# S6E1A1 register map
File version: 1.2
CPU: 
Registers are 32-bit, read-write, reset 0x0 unless marked. A register's access mark holds for its fields unless they carry their own. Offsets are from the block's base; [hi:lo] are bit positions; {n}, {i} and the like mark numbered series.

## LVD — Low-voltage Detection
Base 0x40035000
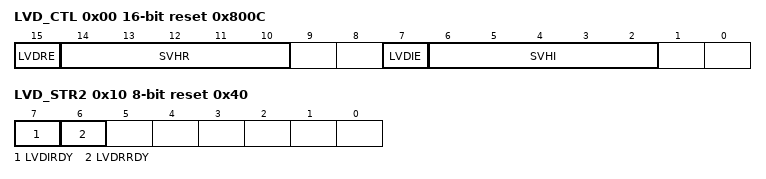
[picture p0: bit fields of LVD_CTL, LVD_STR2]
0x00 LVD_CTL 16-bit reset 0x800C — Low-voltage Detection Voltage Control Register
  [15] LVDRE — Low-voltage detection reset operation enable bit
  [14:10] SVHR — Low-voltage detection reset voltage setting bits
  [7] LVDIE — Low-voltage detection interrupt enable bit
  [6:2] SVHI — Low-voltage detection interrupt voltage setting bits
0x04 LVD_STR 8-bit ro — Low-voltage Detection Interrupt Factor Register
  [7] LVDIR — Low-voltage detection interrupt factor bit
0x08 LVD_CLR 8-bit reset 0x80 — Low-voltage Detection Interrupt Factor Clear Register
  [7] LVDCL — Low-voltage detection interrupt factor clear bit
0x0C LVD_RLR reset 0x1 — Low-voltage Detection Voltage Protection Register
  [31:0] LVDLCK — Low-voltage Detection Voltage Control Register protection bits
0x10 LVD_STR2 8-bit ro reset 0x40 — Low-voltage Detection Circuit Status Register
  [7] LVDIRDY — Low-voltage detection interrupt status flag
  [6] LVDRRDY — Low-voltage detection reset status flag

## DS — Low Power Consumption Mode Registers
Base 0x40035100
0x00 REG_CTL 8-bit reset 0x4 — Sub Oscillation Circuit Power Supply Control Register
  [2:1] ISUBSEL — Sub oscillation circuit current setting bits
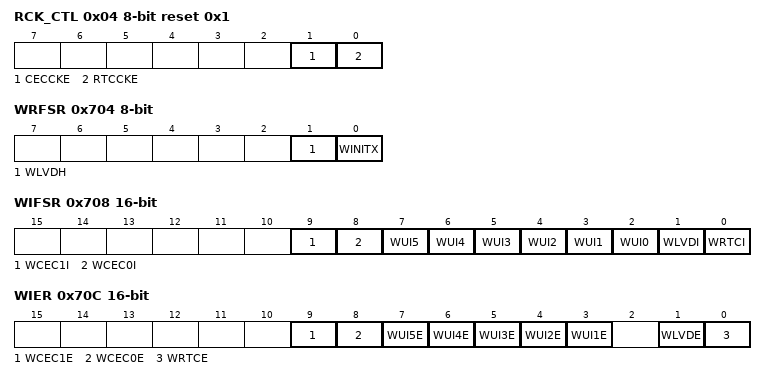
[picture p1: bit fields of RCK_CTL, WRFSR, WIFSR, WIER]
0x04 RCK_CTL 8-bit reset 0x1 — Sub Clock Control Register
  [1] CECCKE — CEC clock control bit
  [0] RTCCKE — RTC clock control bit
0x700 PMD_CTL 8-bit — RTC Mode Control Register
  [0] RTCE — RTC mode control bit
0x704 WRFSR 8-bit ro — Deep Standby Return Factor Register 1
  [1] WLVDH — Low-voltage detection reset return bit
  [0] WINITX — INITX pin input reset return bit
0x708 WIFSR 16-bit ro — Deep Standby Return Factor Register 2
  [9] WCEC1I — CEC ch.1 interrupt return bit
  [8] WCEC0I — CEC ch.0 interrupt return bit
  [n+2] WUI{n} (n=0..5) — WKUP{n} pin input return bit
  [1] WLVDI — LVD interrupt return bit
  [0] WRTCI — RTC interrupt return bit
0x70C WIER 16-bit — Deep Standby Return Enable Register
  [9] WCEC1E — HDMI-CEC/ Remote Control Reception ch.1 interrupt return enable bit
  [8] WCEC0E — HDMI-CEC/ Remote Control Reception ch.0 interrupt return enable bit
  [n+2] WUI{n}E (n=1..5) — WKUP{n} pin input return enable bit
  [1] WLVDE — LVD interrupt return enable bit
  [0] WRTCE — RTC interrupt return enable bit
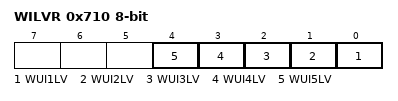
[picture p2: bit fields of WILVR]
0x710 WILVR 8-bit — WKUP Pin Input Level Register
  [n-1] WUI{n}LV (n=1..5) — WKUP{n} pin input level select bit
0x714 DSRAMR 8-bit — Deep Standby RAM Retention Register
  [1:0] SRAMR — On-chip SRAM retention control bits
{0x7FF+i} BUR{i:02} 8-bit (i=1..16) — Backup Register {i:02}

## CRC — CRC Registers
Base 0x40039000
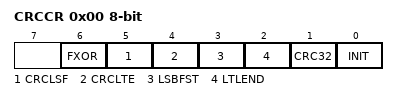
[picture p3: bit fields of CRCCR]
0x00 CRCCR 8-bit — CRC Control Register
  [6] FXOR — Final XOR control bit
  [5] CRCLSF — CRC result bit-order setting bit
  [4] CRCLTE — CRC result byte-order setting bit
  [3] LSBFST — Bit-order setting bit
  [2] LTLEND — Byte-order setting bit
  [1] CRC32 — CRC mode selection bit
  [0] INIT — Initialization bit
0x04 CRCINIT reset 0xFFFFFFFF — Initial Value Register
  [31:0] D — Initial value bits
0x08 CRCIN — Input Data Register
  [31:0] D — Input data bits
0x0C CRCR ro reset 0xFFFFFFFF — CRC Register
  [31:0] D — CRC bits

## WC — Watch Counter
Base 0x4003A000
0x00 WCRD 8-bit ro — Watch Counter Read Register
  [5:0] CTR — Counter read bits
0x01 WCRL 8-bit — Watch Counter Reload Register
  [5:0] RLC — Counter reload value setting bits
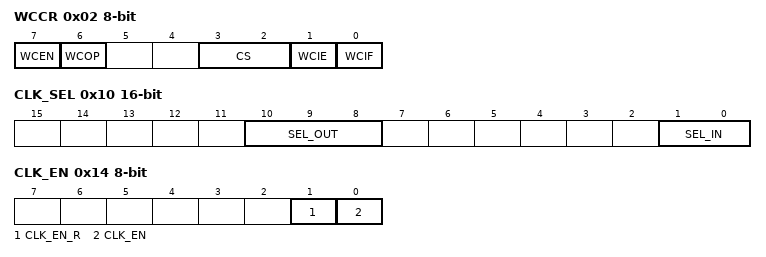
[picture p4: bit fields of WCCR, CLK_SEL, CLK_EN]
0x02 WCCR 8-bit — Watch Counter Control Register
  [7] WCEN — Watch counter operation enable bit
  [6] WCOP ro — Watch counter operating state flag
  [3:2] CS — Count clock select bits
  [1] WCIE — Interrupt request enable bit
  [0] WCIF — Interrupt request flag bit
0x10 CLK_SEL 16-bit — Clock Selection Register
  [10:8] SEL_OUT — Output clock selection bit
  [1:0] SEL_IN — Input clock selection bit
0x14 CLK_EN 8-bit — Division Clock Enable Register
  [1] CLK_EN_R — Division clock enable read bit
  [0] CLK_EN — Division clock enable bit
